# MMC register map
Vendor: Texas Instruments
Registers are 32-bit, access per field, no defined reset value unless marked. A register's access mark holds for its fields unless they carry their own. Offsets are as the file gives them; [hi:lo] are bit positions; {n}, {i} and the like mark numbered series.

## Multimedia_Card (part 2 of 2)
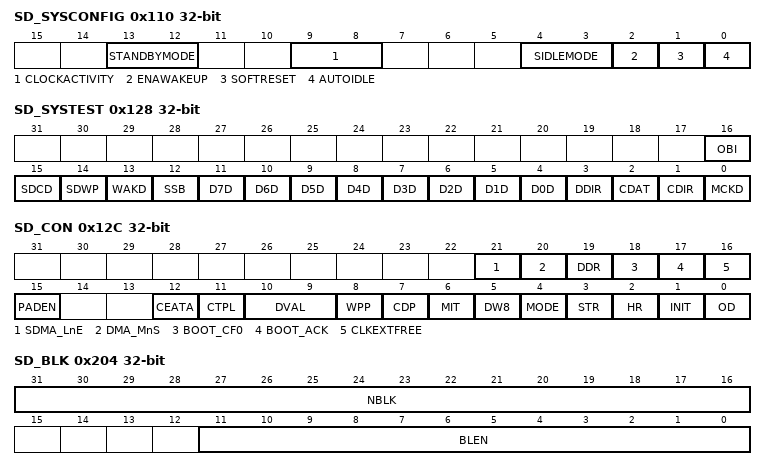
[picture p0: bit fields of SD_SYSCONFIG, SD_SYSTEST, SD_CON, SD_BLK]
0x110 SD_SYSCONFIG — This register allows controlling various parameters of the OCP interface.
  [13:12] STANDBYMODE rw — Master interface power Management, standby/wait control. The bit field is only useful when generic parameter MADMA_EN (Master ADMA enable) is set as active, otherwise it is a read only register read a 0.
  [9:8] CLOCKACTIVITY rw — Clocks activity during wake up mode period. Bit 8 is the Interface clock. Bit 9 is the Functional clock.
  [4:3] SIDLEMODE rw — Power management
  [2] ENAWAKEUP rw — Wake-up feature control
  [1] SOFTRESET rw — Software reset. The bit is automatically reset by the hardware. During reset, it always returns 0.
  [0] AUTOIDLE rw — Internal Clock gating strategy
0x114 SD_SYSSTATUS ro — This register provides status information about the module excluding the interrupt status information.
  [0] RESETDONE — Internal Reset Monitoring. Notethe debounce clock , the interface clock and the functional clock shall be provided to the MMC/SD/SDIO host controller to allow the internal reset monitoring.
0x124 SD_CSRE rw — This register enables the host controller to detect card status errors of response type R1, R1b for all cards and of R5, R5b and R6 response for cards types SD or SDIO. When a bit SD_CSRE[i] is set to 1, if the corresponding bit at the same position in the response SD_RSP10[I] is set to 1, the host controller indicates a card error (SD_STAT[28] CERR bit) interrupt status to avoid the host driver reading the response register (SD_RSP10). No automatic card error detection for autoCMD12 is implemented; the host system has to check autoCMD12 response register (SD_RSP76) for possible card errors.
  [31:0] CSRE — Card status response error
0x128 SD_SYSTEST — This register is used to control the signals that connect to I/O pins when the module is configured in system test (SYSTEST) mode for boundary connectivity verification. In SYSTEST mode, a write into SD_CMD register will not start a transfer. The buffer behaves as a stack accessible only by the local host (push and pop operations). In this mode, the Transfer Block Size (SD_BLK[10:0] BLEN bits) and the Blocks count for current transfer (SD_BLK[31:16] NBLK bits) are needed to generate a Buffer write ready interrupt (SD_STAT[4] BWR bit) or a Buffer read ready interrupt (SD_STAT[5] BRR bit) and DMA requests if enabled.
  [16] OBI rw — Out-of-band interrupt (OBI) data value.
  [15] SDCD rw — Card detect input signal (SDCD) data value
  [14] SDWP rw — Write protect input signal (SDWP) data value
  [13] WAKD rw — Wake request output signal data value.
  [12] SSB rw — Set status bit. This bit must be cleared prior attempting to clear a status bit of the interrupt status register (SD_STAT).
  [n+4] D{n}D rw (n=0..7) — DAT{n} input/output signal data value.
  [3] DDIR rw — Control of the DAT[7:0] pins direction.
  [2] CDAT rw — CMD input/output signal data value
  [1] CDIR rw — Control of the CMD pin direction
  [0] MCKD rw — MMC clock output signal data value
0x12C SD_CON — This register is used: To select the functional mode for any card. To send an initialization sequence to any card. To send an initialization sequence to any card. To enable the detection on the mmc_dat[1] signal of a card interrupt for SDIO cards only. It also configures the parameters related to the card detect and write protect input signals
  [21] SDMA_LnE rw — Slave DMA Level/Edge Request. The waveform of the DMA request can be configured either edge sensitive with early de-assertion on first access to SD_DATA register or late de-assertion, request remains active until last allowed data written into SD_DATA.
  [20] DMA_MnS rw — DMA Master or Slave selection. When this bit is set and the controller is configured to use the DMA, Ocp master interface is used to get datas from system using ADMA2 procedure (direct access to the memory). This option is only available if generic parameter MADMA_EN is asserted to 1.
  [19] DDR rw — Dual Data Rate mode. When this register is set, the controller uses both clock edge to emit or receive data. Odd bytes are transmitted on falling edges and even bytes are transmitted on rise edges. It only applies on Data bytes and CRC, Start, end bits and CRC status are kept full cycle. This bit field is only meaningful and active for even clock divider ratio of SD_SYSCTL[CLKD], it is insensitive to SD_HCTL[HSPE] setting. Note: DDR mode is not supported on AM335x. Always set this bit to 0.
  [18] BOOT_CF0 rw — Boot Status Supported. This register is set when the CMD line needs to be forced to 0 for a boot sequence. CMD line is driven to 0 after writing in SD_CMD. The line is released when this bit field is de-asserted and aborts data transfer in case of a pending transaction.
  [17] BOOT_ACK rw — Book acknowledge received. When this bit is set the controller should receive a boot status on DAT0 line after next command issued. If no status is received a data timeout will be generated.
  [16] CLKEXTFREE rw — External clock free running. This register is used to maintain card clock out of transfer transaction to enable slave module (for example to generate a synchronous interrupt on mmc_dat[1] ). The Clock will be maintain only if SD_SYSCTL[2] CEN bit is set.
  [15] PADEN rw — Control power for MMC lines. This register is only useful when MMC PADs contain power saving mechanism to minimize its leakage power. It works as a GPIO that directly control the ACTIVE pin of PADs. Excepted for mmc_dat[1] , the signal is also combine outside the module with the dedicated power control SD_CON[11] CTPL bit.
  [12] CEATA rw — CE-ATA control mode (MMC cards compliant with CE-ATA). This bit selects the active level of the out-of-band interrupt coming from MMC cards. The usage of the Out-of-Band signal (OBI) is not supported.
  [11] CTPL rw — Control Power for mmc_dat[1] line (SD cards). By default, this bit is cleared to 0 and the host controller automatically disables all the input buffers outside of a transaction to minimize the leakage current. SDIO cards. When this bit is set to 1, the host controller automatically disables all the input buffers except the buffer of mmc_dat[1] outside of a transaction in order to detect asynchronous card interrupt on mmc_dat[1] line and minimize the leakage current of the buffers.
  [10:9] DVAL rw — Debounce filter value (all cards). This register is used to define a debounce period to filter the card detect input signal (SDCD). The usage of the card detect input signal (SDCD) is optional and depends on the system integration and the type of the connector housing that accommodates the card.
  [8] WPP rw — Write protect polarity (SD and SDIO cards only). This bit selects the active level of the write protect input signal (SDWP). The usage of the write protect input signal (SDWP) is optional and depends on the system integration and the type of the connector housing that accommodates the card.
  [7] CDP rw — Card detect polarity (all cards). This bit selects the active level of the write protect input signal (SDWP). The usage of the write protect input signal (SDWP) is optional and depends on the system integration and the type of the connector housing that accommodates the card.
  [6] MIT rw — MMC interrupt command (MMC cards only). This bit must be set to 1, when the next write access to the command register (SD_CMD) is for writing a MMC interrupt command (CMD40) requiring the command timeout detection to be disabled for the command response.
  [5] DW8 rw — 8-bit mode MMC select (MMC cards only). For SD/SDIO cards, this bit must be cleared to 0. For MMC card, this bit must be set following a valid SWITCH command (CMD6) with the correct value and extend CSD index written in the argument. Prior to this command, the MMC card configuration register (CSD and EXT_CSD) must be verified for compliancy with MMC standard specification.
  [4] MODE rw — Mode select (all cards). This bit selects the functional mode.
  [3] STR rw — Stream command (MMC cards only). This bit must be set to 1 only for the stream data transfers (read or write) of the adtc commands. Stream read is a class 1 command (CMD11READ_DAT_UNTIL_STOP). Stream write is a class 3 command (CMD20WRITE_DAT_UNTIL_STOP).
  [2] HR rw — Broadcast host response (MMC cards only). This register is used to force the host to generate a 48-bit response for bc command type. It can be used to terminate the interrupt mode by generating a CMD40 response by the core. In order to have the host response to be generated in open drain mode, the register SD_CON[OD] must be set to 1. When SD_CON[12] CEATA bit is set to 1 and SD_ARG cleared to 0, when writing 0000 0000h into SD_CMD register, the host controller performs a 'command completion signal disable' token (i.e., mmc_cmd line held to 0 during 47 cycles followed by a 1).
  [1] INIT rw — Send initialization stream (all cards). When this bit is set to 1, and the card is idle, an initialization sequence is sent to the card. An initialization sequence consists of setting the mmc_cmd line to 1 during 80 clock cycles. The initialization sequence is mandatory - but it is not required to do it through this bit - this bit makes it easier. Clock divider (SD_SYSCTL[15:6] CLKD bits) should be set to ensure that 80 clock periods are greater than 1ms. Note: In this mode, there is no command sent to the card and no response is expected. A command complete interrupt will be generated once the initialization sequence is completed. SD_STAT[0] CC bit can be polled.
  [0] OD rw — Card open drain mode (MMC cards only). This bit must be set to 1 for MMC card commands 1, 2, 3 and 40, and if the MMC card bus is operating in open-drain mode during the response phase to the command sent. Typically, during card identification mode when the card is either in idle, ready or ident state. It is also necessary to set this bit to 1, for a broadcast host response (see Broadcast host response register SD_CON[2] HR bit).
0x130 SD_PWCNT — This register is used to program a mmc counter to delay command transfers after activating the PAD power, this value depends on PAD characteristics and voltage.
  [15:0] PWRCNT rw — Power counter register. This register is used to introduce a delay between the PAD ACTIVE pin assertion and the command issued.
0x200 SD_SDMASA ro — This register is used to program a mmc counter to delay command transfers after activating the PAD power. This value depends on PAD characteristics and voltage.
  [31:0] SDMA_SYSADDR — This register contains the system memory address for a SDMA transfer. When the Host Controller stops a SDMA transfer, this register shall point to the system address of the next contiguous data position. It can be accessed only if no transaction is executing (i.e., after a transaction has stopped). Read operations during transfers may return an invalid value. The Host Driver shall initialize this register before starting a SDMA transaction. After SDMA has stopped, the next system address of the next contiguous data position can be read from this register. The SDMA transfer waits at the every boundary specified by the Host SDMA Buffer Boundary in the Block Size register. The Host Controller generates DMA Interrupt to request the Host Driver to update this register. The Host Driver sets the next system address of the next data position to this register. When the most upper byte of this register (003h) is written, the Host Controller restarts the SDMA transfer. When restarting SDMA by the Resume command or by setting Continue Request in the Block Gap Control register, the Host Controller shall start at the next contiguous address stored here in the SDMA System Address register. ADMA does not use this register.
0x204 SD_BLK — This register shall be used for any card. SD_BLK[BLEN] is the block size register. SD_BLK[NBLK] is the block count register.
  [31:16] NBLK rw — Blocks count for current transfer. This register is enabled when Block count Enable (SD_CMD[1] BCE bit) is set to 1 and is valid only for multiple block transfers. Setting the block count to 0 results no data blocks being transferred. Note: The host controller decrements the block count after each block transfer and stops when the count reaches zero. This register can be accessed only if no transaction is executing (i.e., after a transaction has stopped). Read operations during transfers may return an invalid value and write operation will be ignored. In suspend context, the number of blocks yet to be transferred can be determined by reading this register. When restoring transfer context prior to issuing a Resume command, The local host shall restore the previously saved block count.
  [11:0] BLEN rw — Transfer block size. This register specifies the block size for block data transfers. Read operations during transfers may return an invalid value, and write operations are ignored. When a CMD12 command is issued to stop the transfer, a read of the BLEN field after transfer completion (SD_STAT[1] TC bit set to 1) will not return the true byte number of data length while the stop occurs but the value written in this register before transfer is launched.
0x208 SD_ARG rw — This register contains command argument specified as bit 39-8 of Command-Format. These registers must be initialized prior to sending the command itself to the card (write action into the register SD_CMD register). Only exception is for a command index specifying stuff bits in arguments, making a write unnecessary.
  [31:0] ARG — Command argument bits [31:0] .
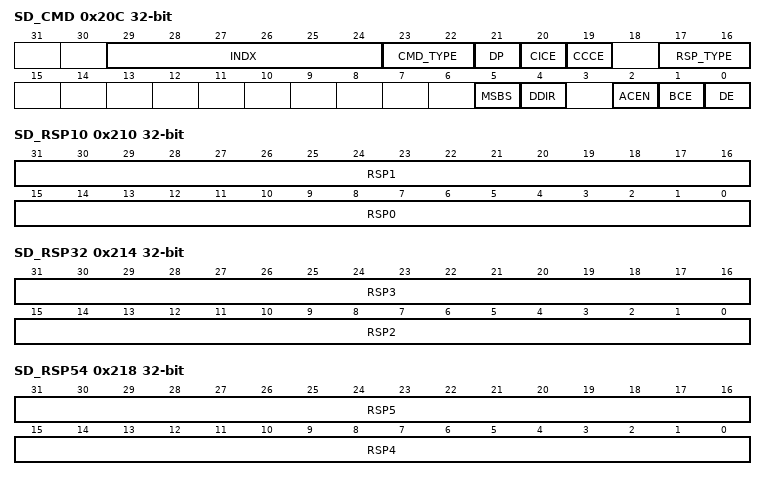
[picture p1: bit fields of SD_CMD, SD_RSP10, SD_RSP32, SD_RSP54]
0x20C SD_CMD — SD_CMD[31:16] = the command register. SD_CMD[15:0] = the transfer mode. This register configures the data and command transfers. A write into the most significant byte send the command. A write into SD_CMD[15:0] registers during data transfer has no effect. This register can be used for any card. In SYSTEST mode, a write into SD_CMD register will not start a transfer.
  [29:24] INDX rw — Command index binary encoded value from 0 to 63 specifying the command number send to card.
  [23:22] CMD_TYPE rw — Command type. This register specifies three types of special commands: Suspend, Resume and Abort. These bits shall be cleared to 0b00 for all other commands.
  [21] DP rw — Data present select. This register indicates that data is present and mmc_dat line shall be used. It must be cleared to 0 in the following conditions: Command using only mmc_cmd line. Command with no data transfer but using busy signal on mmc_dat0. Resume command.
  [20] CICE rw — Command Index check enable. This bit must be set to 1 to enable index check on command response to compare the index field in the response against the index of the command. If the index is not the same in the response as in the command, it is reported as a command index error (SD_STAT[19] CIE bit set to1) NoteThe CICE bit cannot be configured for an Auto CMD12, then index check is automatically checked when this command is issued.
  [19] CCCE rw — Command CRC check enable. This bit must be set to 1 to enable CRC7 check on command response to protect the response against transmission errors on the bus. If an error is detected, it is reported as a command CRC error (SD_STAT[17] CCRC bit set to 1). NoteThe CCCE bit cannot be configured for an Auto CMD12, and then CRC check is automatically checked when this command is issued.
  [17:16] RSP_TYPE rw — Response type. This bits defines the response type of the command.
  [5] MSBS rw — Multi/Single block select. This bit must be set to 1 for data transfer in case of multi block command. For any others command this bit shall be cleared to 0.
  [4] DDIR rw — Data transfer Direction. Select This bit defines either data transfer will be a read or a write.
  [2] ACEN rw — Auto CMD12 Enable (SD cards only). When this bit is set to 1, the host controller issues a CMD12 automatically after the transfer completion of the last block. The Host Driver shall not set this bit to issue commands that do not require CMD12 to stop data transfer. In particular, secure commands do not require CMD12. For CE-ATA commands (SD_CON[12] CEATA bit set to 1), auto CMD12 is useless; therefore when this bit is set the mechanism to detect command completion signal, named CCS, interrupt is activated.
  [1] BCE rw — Block Count Enable (Multiple block transfers only). This bit is used to enable the block count register (SD_BLK[31:16] NBLK bits). When Block Count is disabled (SD_CMD[1] BCE bit is cleared to 0) in Multiple block transfers (SD_CMD[5] MSBS bits is set to 1), the module can perform infinite transfer.
  [0] DE rw — DMA Enable. This bit is used to enable DMA mode for host data access.
0x210 SD_RSP10 ro — This 32-bit register holds bits positions [31:0] of command response type R1, R1b, R2, R3, R4, R5, R5b, or R6.
  [31:16] RSP1 — Command Response [31:16]
  [15:0] RSP0 — Command Response [15:0]
0x214 SD_RSP32 ro — This 32-bit register holds bits positions [63:32] of command response type R2.
  [31:16] RSP3 — Command Response [63:48]
  [15:0] RSP2 — Command Response [47:32]
0x218 SD_RSP54 ro — This 32-bit register holds bits positions [95:64] of command response type R2.
  [31:16] RSP5 — Command Response [95:80]
  [15:0] RSP4 — Command Response [79:64]
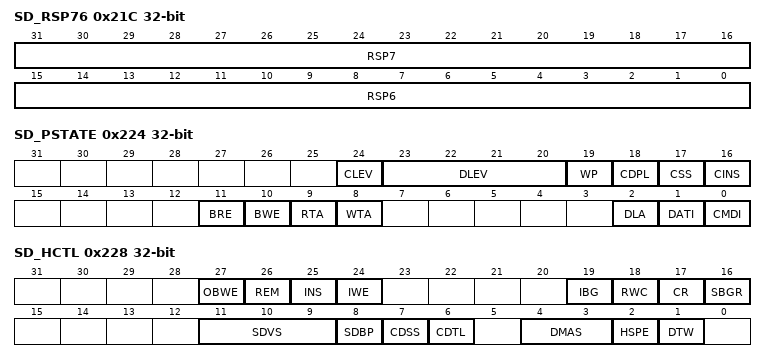
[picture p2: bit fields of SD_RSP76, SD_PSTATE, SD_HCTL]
0x21C SD_RSP76 ro — This 32-bit register holds bits positions [127:96] of command response type R2.
  [31:16] RSP7 — Command Response [127:112]
  [15:0] RSP6 — Command Response [111:96]
0x220 SD_DATA rw — This register is the 32-bit entry point of the buffer for read or write data transfers. The buffer size is 32bitsx256(1024 bytes). Bytes within a word are stored and read in little endian format. This buffer can be used as two 512 byte buffers to transfer data efficiently without reducing the throughput. Sequential and contiguous access is necessary to increment the pointer correctly. Random or skipped access is not allowed. In little endian, if the local host accesses this register byte-wise or 16bit-wise, the least significant byte (bits [7:0]) must always be written/read first. The update of the buffer address is done on the most significant byte write for full 32-bit DATA register or on the most significant byte of the last word of block transfer. Example 1Byte or 16-bit access: Mbyteen[3:0]=0001 (1-byte) => Mbyteen[3:0]=0010 (1-byte) => Mbyteen[3:0]=1100 (2-bytes) OK. Mbyteen[3:0]=0001 (1-byte) => Mbyteen[3:0]=0010 (1-byte) => Mbyteen[3:0]=0100 (1-byte) OK. Mbyteen[3:0]=0001 (1-byte) => Mbyteen[3:0]=0010 (1-byte) => Mbyteen[3:0]=1000 (1-byte) Bad.
  [31:0] DATA — Data register [31:0]. In functional mode (SD_CON[4] MODE bit set to the default value 0): A read access to this register is allowed only when the buffer read enable status is set to 1 (SD_PSTATE[11] BRE bit), otherwise a bad access (SD_STAT[29] BADA bit) is signaled. A write access to this register is allowed only when the buffer write enable status is set to 1 (SD_PSTATE[10] BWE bit), otherwise a bad access (SD_STAT[29] BADA bit) is signaled and the data is not written.
0x224 SD_PSTATE ro — The Host can get the status of the Host controller from this 32-bit read only register.
  [24] CLEV — mmc_cmd line signal level. This status is used to check the mmc_cmd line level to recover from errors, and for debugging. The value of this register after reset depends on the mmc_cmd line level at that time.
  [23:20] DLEV — mmc_dat[3:0] line signal level mmc_dat3 equal to or greater than bit 23. mmc_dat2 equal to or greater than bit 22. mmc_dat1 equal to or greater than bit 21. mmc_dat0 equal to or greater than bit 20. This status is used to check mmc_dat line level to recover from errors, and for debugging. This is especially useful in detecting the busy signal level from mmc_dat0 . The value of these registers after reset depends on the mmc_dat lines level at that time.
  [19] WP — Write Protect. MMC/SD/SDIO1 only. SDIO cards only. This bit reflects the write protect input pin (SDWP) level. The value of this register after reset depends one the protect input pin (SDWP) level at that time.
  [18] CDPL — Card Detect Pin Level. MMC/SD/SDIO1 only. SDIO cards only. This bit reflects the inverse value of the card detect input pin (SDCD). Debouncing is not performed on this bit and is valid only when Card State is stable. (SD_PSTATE[17] is set to 1). This bit must be debounced by software. The value of this register after reset depends on the card detect input pin (SDCD) level at that time.
  [17] CSS — Card State Stable. This bit is used for testing. It is set to 1 only when Card Detect Pin Level is stable (SD_PSTATE[18] CPDL). Debouncing is performed on the card detect input pin (SDCD) to detect card stability. This bit is not affected by software reset.
  [16] CINS — Card inserted. This bit is the debounced value of the card detect input pin (SDCD). An inactive to active transition of the card detect input pin (SDCD) will generate a card insertion interrupt (SD_STAT[CINS]). A active to inactive transition of the card detect input pin (SDCD) will generate a card removal interrupt (SD_STAT[REM]). This bit is not affected by a software reset.
  [11] BRE — Buffer read enable. This bit is used for non-DMA read transfers. It indicates that a complete block specified by SD_BLK[10:0] BLEN bits has been written in the buffer and is ready to be read. It is cleared to 0 when the entire block is read from the buffer. It is set to 1 when a block data is ready in the buffer and generates the Buffer read ready status of interrupt (SD_STAT[5] BRR bit).
  [10] BWE — Buffer Write enable. This status is used for non-DMA write transfers. It indicates if space is available for write data.
  [9] RTA — Read transfer active. This status is used for detecting completion of a read transfer. It is set to 1 after the end bit of read command or by activating a continue request (SD_HCTL[17] CR bit) following a stop at block gap request. This bit is cleared to 0 when all data have been read by the local host after last block or after a stop at block gap request.
  [8] WTA — Write transfer active. This status indicates a write transfer active. It is set to 1 after the end bit of write command or by activating a continue request (SD_HCTL[17] CR bit) following a stop at block gap request. This bit is cleared to 0 when CRC status has been received after last block or after a stop at block gap request.
  [2] DLA — mmc_dat line active. This status bit indicates whether one of the mmc_dat lines is in use. In the case of read transactions (card to host)This bit is set to 1 after the end bit of read command or by activating continue request SD_HCTL[17] CR bit. This bit is cleared to 0 when the host controller received the end bit of the last data block or at the beginning of the read wait mode. In the case of write transactions (host to card)This bit is set to 1 after the end bit of write command or by activating continue request SD_HCTL[17] CR bit. This bit is cleared to 0 on the end of busy event for the last block. The host controller must wait 8 clock cycles with line not busy to really consider not "busy state" or after the busy block as a result of a stop at gap request.
  [1] DATI — Command inhibit (mmc_dat). This status bit is generated if either mmc_dat line is active (SD_PSTATE[2] DLA bit) or Read transfer is active (SD_PSTATE[9] RTA bit) or when a command with busy is issued. This bit prevents the local host to issue a command. A change of this bit from 1 to 0 generates a transfer complete interrupt (SD_STAT[1] TC bit).
  [0] CMDI — Command inhibit(mmc_cmd). This status bit indicates that the mmc_cmd line is in use. This bit is cleared to 0 when the most significant byte is written into the command register. This bit is not set when Auto CMD12 is transmitted. This bit is cleared to 0 in either the following cases: After the end bit of the command response, excepted if there is a command conflict error (SD_STAT[17] CCRC bit or SD_STAT[18] CEB bit set to 1) or a Auto CMD12 is not executed (SD_AC12[0] ACNE bit). After the end bit of the command without response (SD_CMD[17:16] RSP_TYPE bits set to "00"). In case of a command data error is detected (SD_STAT[19] CTO bit set to 10, this register is not automatically cleared.
0x228 SD_HCTL — This register defines the host controls to set power, wake-up and transfer parameters. SD_HCTL[31:24] = Wake-up control. SD_HCTL[23:16] = Block gap control. SD_HCTL[15:8] = Power control. SD_HCTL[7:0] = Host control. If your device does not support MMC cards, then those bits in this register which are meant for MMC card use should be assumed to be reserved.
  [27] OBWE rw — Wake-up event enable for 'out-of-band' Interrupt. This bit enables wake-up events for 'out-of-band' assertion. Wake-up is generated if the wake-up feature is enabled (SD_SYSCONFIG[2] ENAWAKEUP bit). The write to this register is ignored when SD_CON[14] OBIE bit is not set.
  [26] REM rw — Wake-up event enable on SD card removal. This bit enables wake-up events for card removal assertion. Wake-up is generated if the wake-up feature is enabled (SD_SYSCONFIG[2] ENAWAKEUP bit).
  [25] INS rw — Wake-up event enable on SD card insertion This bit enables wake-up events for card insertion assertion. Wake-up is generated if the wake-up feature is enabled (SD_SYSCONFIG[2] ENAWAKEUP bit).
  [24] IWE rw — Wake-up event enable on SD card interrupt. This bit enables wake-up events for card interrupt assertion. Wake-up is generated if the wake-up feature is enabled (SD_SYSCONFIG[2] ENAWAKEUP bit) and enable status bit is set (SD_IE[8] CIRQ_ENABLE bit).
  [19] IBG rw — Interrupt block at gap. This bit is valid only in 4-bit mode of SDIO card to enable interrupt detection in the interrupt cycle at block gap for a multiple block transfer. For MMC cards and for SD card this bit should be cleared to 0.
  [18] RWC rw — Read wait control. The read wait function is optional only for SDIO cards. If the card supports read wait, this bit must be enabled, then requesting a stop at block gap (SD_HCTL[16] SBGR bit) generates a read wait period after the current end of block. Be careful, if read wait is not supported it may cause a conflict on mmc_dat line.
  [17] CR rw — Continue request. This bit is used to restart a transaction that was stopped by requesting a stop at block gap (SD_HCTL[16] SBGR bit). Set this bit to 1 restarts the transfer. The bit is automatically cleared to 0 by the host controller when transfer has restarted, that is, mmc_dat line is active (SD_PSTATE[2] DLA bit) or transferring data (SD_PSTATE[8] WTA bit). The Stop at block gap request must be disabled (SD_HCTL[16] SBGR bit =0) before setting this bit.
  [16] SBGR rw — Stop at block gap request. This bit is used to stop executing a transaction at the next block gap. The transfer can restart with a continue request (SD_HCTL[17] CR bit) or during a suspend/resume sequence. In case of read transfer, the card must support read wait control. In case of write transfer, the host driver shall set this bit after all block data written. Until the transfer completion (SD_STAT[1] TC bit set to 1), the host driver shall leave this bit set to 1.If this bit is set, the local host shall not write to the data register (SD_DATA).
  [11:9] SDVS rw — SD bus voltage select (All cards). The host driver should set these bits to select the voltage level for the card according to the voltage supported by the system (SD_CAPA[26] VS18 bit, SD_CAPA[25] VS30 bit, SD_CAPA[24] VS33 bit) before starting a transfer. If MMCHS2: This field must be set to 5h. If MMCHS3: This field must be set to 5h.
  [8] SDBP rw — SD bus power. Before setting this bit, the host driver shall select the SD bus voltage (SD_HCTL[11:9] SDVS bits). If the host controller detects the No card state, this bit is automatically cleared to 0. If the module is power off, a write in the command register (SD_CMD) will not start the transfer. A write to this bit has no effect if the selected SD bus voltage is not supported according to capability register (SD_CAPA[VS*]).
  [7] CDSS rw — Card Detect Signal Selection. This bit selects source for the card detection. When the source for the card detection is switched, the interrupt should be disabled during the switching period by clearing the Interrupt Status/Signal Enable register in order to mask unexpected interrupt being caused by the glitch. The Interrupt Status/Signal Enable should be disabled during over the period of debouncing.
  [6] CDTL rw — Card Detect Test Level. This bit is enabled while the Card Detect Signal Selection is set to 1 and it indicates card inserted or not. 0 = No card 1 = Card inserted.
  [4:3] DMAS rw — DMA Select. One of the supported DMA modes can be selected. The host driver shall check support of DMA modes by referencing the Capabilities register. Use of selected DMA is determined by DMA Enable of the Transfer Mode register. This register is only meaningful when MADMA_EN is set to 1. When MADMA_EN is cleared to 0 the bit field is read only and returned value is 0.
  [2] HSPE rw — High Speed Enable. Before setting this bit, the Host Driver shall check the High Speed Support in the Capabilities register. If this bit is cleared to 0 (default), the Host Controller outputs CMD line and DAT lines at the falling edge of the SD Clock. If this bit is set to 1, the Host Controller outputs CMD line and DAT lines at the rising edge of the SD Clock. This bit shall not be set when dual data rate mode is activated in SD_CON[DDR].
  [1] DTW rw — Data transfer width. This bit must be set following a valid SET_BUS_WIDTH command (ACMD6) with the value written in bit 1 of the argument. Prior to this command, the SD card configuration register (SCR) must be verified for the supported bus width by the SD card.
